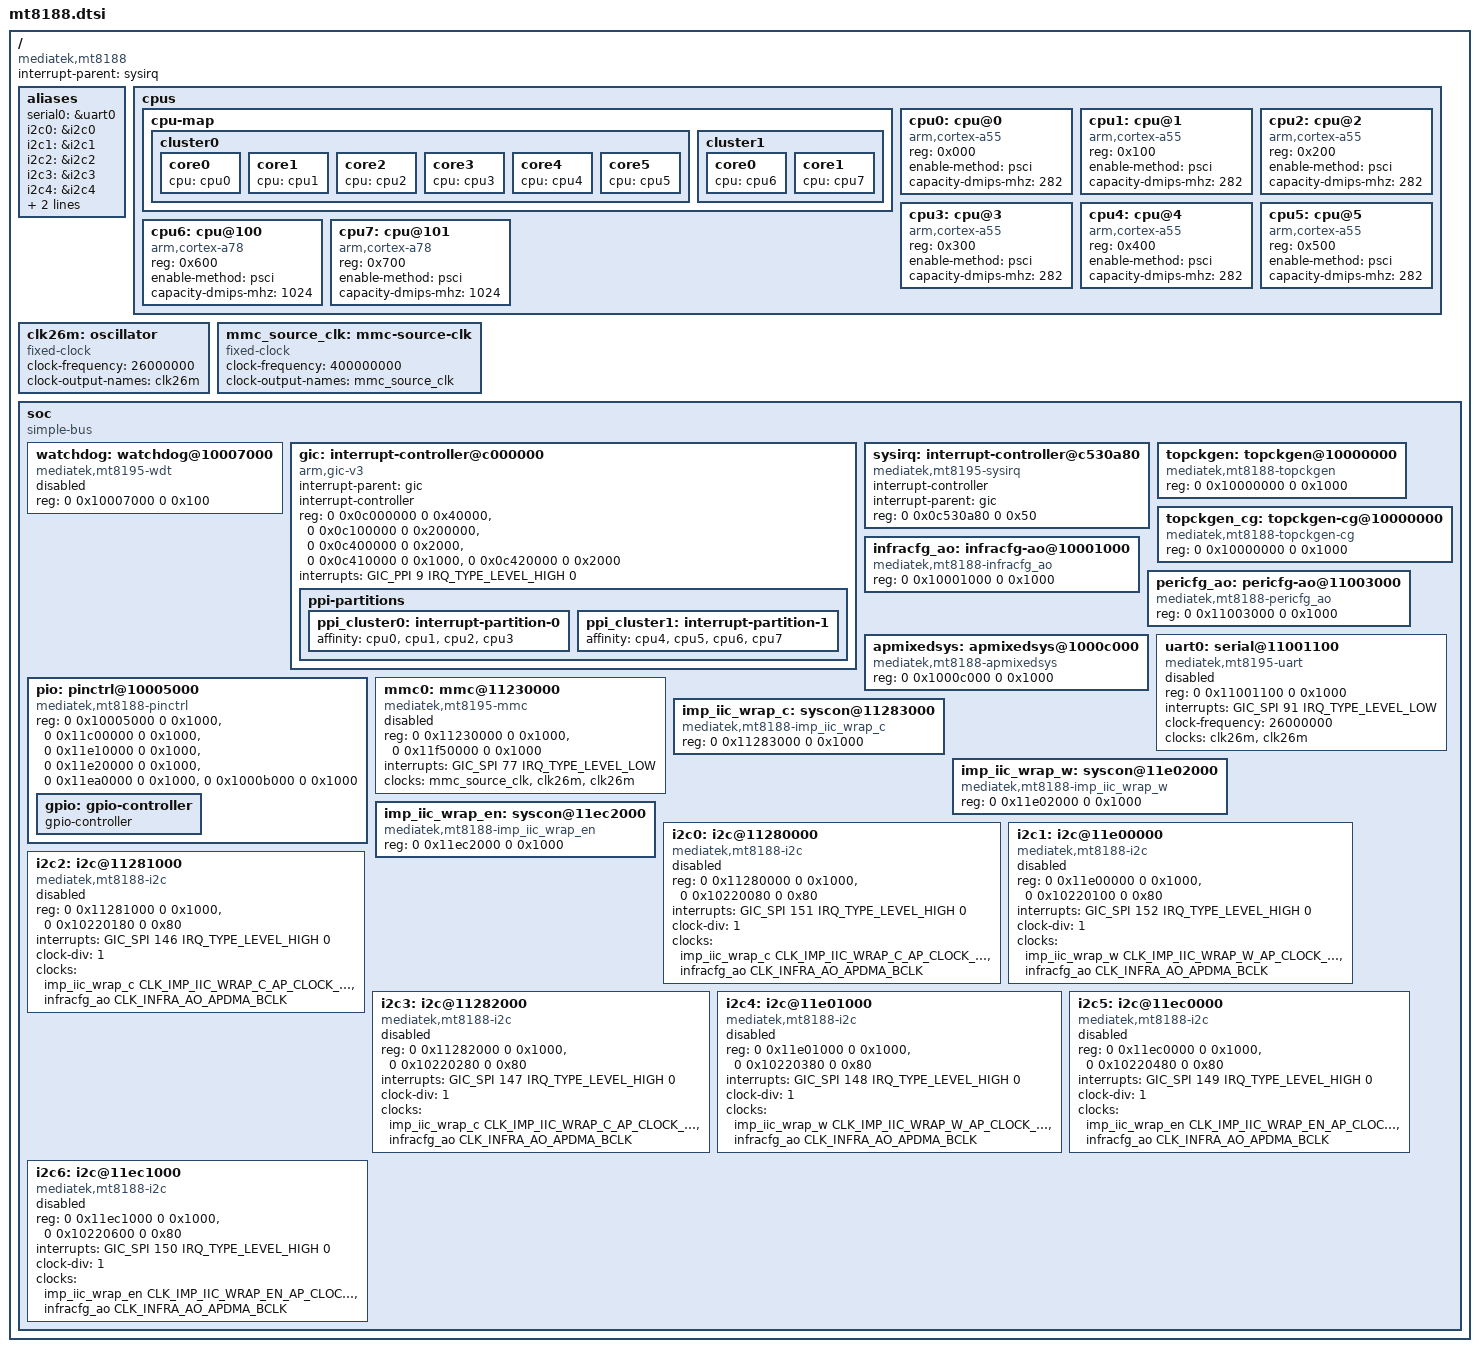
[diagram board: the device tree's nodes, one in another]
// SPDX-License-Identifier: (GPL-2.0 OR MIT)
/*
 * Copyright (C) 2022 MediaTek Inc.
 * Author: Chris-QJ Chen <chris-qj.chen@mediatek.com>
 *         Macpaul Lin <macpaul.lin@mediatek.com>
 */

#include <dt-bindings/gpio/gpio.h>
#include <dt-bindings/clock/mt8188-clk.h>
#include <dt-bindings/interrupt-controller/irq.h>
#include <dt-bindings/interrupt-controller/arm-gic.h>
#include <dt-bindings/pinctrl/mediatek,mt8188-pinfunc.h>
#include <dt-bindings/phy/phy.h>

/ {
	compatible = "mediatek,mt8188";
	interrupt-parent = <&sysirq>;
	#address-cells = <2>;
	#size-cells = <2>;

	aliases {
		serial0 = &uart0;
		i2c0 = &i2c0;
		i2c1 = &i2c1;
		i2c2 = &i2c2;
		i2c3 = &i2c3;
		i2c4 = &i2c4;
		i2c5 = &i2c5;
		i2c6 = &i2c6;
	};

	cpus {
		#address-cells = <1>;
		#size-cells = <0>;

		cpu-map {
			cluster0 {
				core0 {
					cpu = <&cpu0>;
				};
				core1 {
					cpu = <&cpu1>;
				};
				core2 {
					cpu = <&cpu2>;
				};
				core3 {
					cpu = <&cpu3>;
				};
				core4 {
					cpu = <&cpu4>;
				};
				core5 {
					cpu = <&cpu5>;
				};
			};
			cluster1 {
				core0 {
					cpu = <&cpu6>;
				};
				core1 {
					cpu = <&cpu7>;
				};
			};
		};

		cpu0: cpu@0 {
			device_type = "cpu";
			compatible = "arm,cortex-a55", "arm,armv8";
			reg = <0x000>;
			enable-method = "psci";
			capacity-dmips-mhz = <282>;
		};

		cpu1: cpu@1 {
			device_type = "cpu";
			compatible = "arm,cortex-a55", "arm,armv8";
			reg = <0x100>;
			enable-method = "psci";
			capacity-dmips-mhz = <282>;
		};

		cpu2: cpu@2 {
			device_type = "cpu";
			compatible = "arm,cortex-a55", "arm,armv8";
			reg = <0x200>;
			enable-method = "psci";
			capacity-dmips-mhz = <282>;
		};

		cpu3: cpu@3 {
			device_type = "cpu";
			compatible = "arm,cortex-a55", "arm,armv8";
			reg = <0x300>;
			enable-method = "psci";
			capacity-dmips-mhz = <282>;
		};

		cpu4: cpu@4 {
			device_type = "cpu";
			compatible = "arm,cortex-a55", "arm,armv8";
			reg = <0x400>;
			enable-method = "psci";
			capacity-dmips-mhz = <282>;
		};

		cpu5: cpu@5 {
			device_type = "cpu";
			compatible = "arm,cortex-a55", "arm,armv8";
			reg = <0x500>;
			enable-method = "psci";
			capacity-dmips-mhz = <282>;
		};

		cpu6: cpu@100 {
			device_type = "cpu";
			compatible = "arm,cortex-a78", "arm,armv8";
			reg = <0x600>;
			enable-method = "psci";
			capacity-dmips-mhz = <1024>;
		};

		cpu7: cpu@101 {
			device_type = "cpu";
			compatible = "arm,cortex-a78", "arm,armv8";
			reg = <0x700>;
			enable-method = "psci";
			capacity-dmips-mhz = <1024>;
		};
	};

	clk26m: oscillator {
		compatible = "fixed-clock";
		#clock-cells = <0>;
		clock-frequency = <26000000>;
		clock-output-names = "clk26m";
	};

	mmc_source_clk: mmc-source-clk{
		compatible = "fixed-clock";
		#clock-cells = <0>;
		clock-frequency = <400000000>;
		clock-output-names = "mmc_source_clk";
	};

	soc {
		#address-cells = <2>;
		#size-cells = <2>;
		compatible = "simple-bus";
		ranges;

		watchdog: watchdog@10007000 {
			compatible = "mediatek,mt8195-wdt",
				      "mediatek,wdt";
			reg = <0 0x10007000 0 0x100>;
			status = "disabled";
		};

		gic: interrupt-controller@c000000 {
			compatible = "arm,gic-v3";
			#interrupt-cells = <4>;
			interrupt-parent = <&gic>;
			interrupt-controller;
			reg = <0 0x0c000000 0 0x40000>,  /* GICD */
			      <0 0x0c100000 0 0x200000>, /* GICR */
			      <0 0x0c400000 0 0x2000>,   /* GICC */
			      <0 0x0c410000 0 0x1000>,   /* GICH */
			      <0 0x0c420000 0 0x2000>;   /* GICV */

			interrupts = <GIC_PPI 9 IRQ_TYPE_LEVEL_HIGH 0>;
			ppi-partitions {
				ppi_cluster0: interrupt-partition-0 {
					affinity = <&cpu0 &cpu1 &cpu2 &cpu3>;
				};
				ppi_cluster1: interrupt-partition-1 {
					affinity = <&cpu4 &cpu5 &cpu6 &cpu7>;
				};
			};
		};

		sysirq: interrupt-controller@c530a80 {
			compatible = "mediatek,mt8195-sysirq",
				     "mediatek,mt6577-sysirq";
			interrupt-controller;
			#interrupt-cells = <3>;
			interrupt-parent = <&gic>;
			reg = <0 0x0c530a80 0 0x50>;
		};

		topckgen: topckgen@10000000 {
			compatible = "mediatek,mt8188-topckgen";
			reg = <0 0x10000000 0 0x1000>;
			#clock-cells = <1>;
		};

		topckgen_cg: topckgen-cg@10000000 {
			compatible = "mediatek,mt8188-topckgen-cg";
			reg = <0 0x10000000 0 0x1000>;
			#clock-cells = <1>;
		};

		infracfg_ao: infracfg-ao@10001000 {
			compatible = "mediatek,mt8188-infracfg_ao";
			reg = <0 0x10001000 0 0x1000>;
			#clock-cells = <1>;
		};

		pericfg_ao: pericfg-ao@11003000 {
			compatible = "mediatek,mt8188-pericfg_ao";
			reg = <0 0x11003000 0 0x1000>;
			#clock-cells = <1>;
		};

		apmixedsys: apmixedsys@1000c000 {
			compatible = "mediatek,mt8188-apmixedsys";
			reg = <0 0x1000c000 0 0x1000>;
			#clock-cells = <1>;
		};

		pio: pinctrl@10005000 {
			compatible = "mediatek,mt8188-pinctrl";
			reg = <0 0x10005000 0 0x1000>,
			<0 0x11c00000 0 0x1000>,
			<0 0x11e10000 0 0x1000>,
			<0 0x11e20000 0 0x1000>,
			<0 0x11ea0000 0 0x1000>,
			<0 0x1000b000 0 0x1000>;
			reg-names = "iocfg0", "iocfg_rm", "iocfg_lt",
				    "iocfg_lm", "iocfg_rt", "eint";
			gpio: gpio-controller {
				gpio-controller;
				#gpio-cells = <2>;
			};
		};

		uart0: serial@11001100 {
			compatible = "mediatek,mt8195-uart",
				     "mediatek,hsuart";
			reg = <0 0x11001100 0 0x1000>;
			interrupts = <GIC_SPI 91 IRQ_TYPE_LEVEL_LOW>;
			clock-frequency = <26000000>;
			clocks = <&clk26m>, <&clk26m>;
			clock-names = "baud", "bus";
			status = "disabled";
		};

		mmc0: mmc@11230000 {
			compatible = "mediatek,mt8195-mmc",
				     "mediatek,mt8183-mmc";
			reg = <0 0x11230000 0 0x1000>,
			      <0 0x11f50000 0 0x1000>;
			interrupts = <GIC_SPI 77 IRQ_TYPE_LEVEL_LOW>;
			clocks = <&mmc_source_clk>,
				 <&clk26m>,
				 <&clk26m>;
			clock-names = "source", "hclk", "source_cg";
			status = "disabled";
		};

		imp_iic_wrap_c: syscon@11283000 {
			compatible = "mediatek,mt8188-imp_iic_wrap_c";
			reg = <0 0x11283000 0 0x1000>;
			#clock-cells = <1>;
		};

		imp_iic_wrap_w: syscon@11e02000 {
			compatible = "mediatek,mt8188-imp_iic_wrap_w";
			reg = <0 0x11e02000 0 0x1000>;
			#clock-cells = <1>;
		};

		imp_iic_wrap_en: syscon@11ec2000 {
			compatible = "mediatek,mt8188-imp_iic_wrap_en";
			reg = <0 0x11ec2000 0 0x1000>;
			#clock-cells = <1>;
		};

		i2c0: i2c@11280000 {
			compatible = "mediatek,mt8188-i2c";
			reg = <0 0x11280000 0 0x1000>,
			      <0 0x10220080 0 0x80>;
			interrupts = <GIC_SPI 151 IRQ_TYPE_LEVEL_HIGH 0>;
			clock-div = <1>;
			clocks = <&imp_iic_wrap_c CLK_IMP_IIC_WRAP_C_AP_CLOCK_I2C0>,
				 <&infracfg_ao CLK_INFRA_AO_APDMA_BCLK>;
			clock-names = "main", "dma";
			#address-cells = <1>;
			#size-cells = <0>;
			status = "disabled";
		};

		i2c1: i2c@11e00000 {
			compatible = "mediatek,mt8188-i2c";
			reg = <0 0x11e00000 0 0x1000>,
			      <0 0x10220100 0 0x80>;
			interrupts = <GIC_SPI 152 IRQ_TYPE_LEVEL_HIGH 0>;
			clock-div = <1>;
			clocks = <&imp_iic_wrap_w CLK_IMP_IIC_WRAP_W_AP_CLOCK_I2C1>,
				 <&infracfg_ao CLK_INFRA_AO_APDMA_BCLK>;
			clock-names = "main", "dma";
			#address-cells = <1>;
			#size-cells = <0>;
			status = "disabled";
		};

		i2c2: i2c@11281000 {
			compatible = "mediatek,mt8188-i2c";
			reg = <0 0x11281000 0 0x1000>,
				<0 0x10220180 0 0x80>;
			interrupts = <GIC_SPI 146 IRQ_TYPE_LEVEL_HIGH 0>;
			clock-div = <1>;
			clocks = <&imp_iic_wrap_c CLK_IMP_IIC_WRAP_C_AP_CLOCK_I2C2>,
				 <&infracfg_ao CLK_INFRA_AO_APDMA_BCLK>;
			clock-names = "main", "dma";
			#address-cells = <1>;
			#size-cells = <0>;
			status = "disabled";
		};

		i2c3: i2c@11282000 {
			compatible = "mediatek,mt8188-i2c";
			reg = <0 0x11282000 0 0x1000>,
			      <0 0x10220280 0 0x80>;
			interrupts = <GIC_SPI 147 IRQ_TYPE_LEVEL_HIGH 0>;
			clock-div = <1>;
			clocks = <&imp_iic_wrap_c CLK_IMP_IIC_WRAP_C_AP_CLOCK_I2C3>,
				 <&infracfg_ao CLK_INFRA_AO_APDMA_BCLK>;
			clock-names = "main", "dma";
			#address-cells = <1>;
			#size-cells = <0>;
			status = "disabled";
		};

		i2c4: i2c@11e01000 {
			compatible = "mediatek,mt8188-i2c";
			reg = <0 0x11e01000 0 0x1000>,
			      <0 0x10220380 0 0x80>;
			interrupts = <GIC_SPI 148 IRQ_TYPE_LEVEL_HIGH 0>;
			clock-div = <1>;
			clocks = <&imp_iic_wrap_w CLK_IMP_IIC_WRAP_W_AP_CLOCK_I2C4>,
				 <&infracfg_ao CLK_INFRA_AO_APDMA_BCLK>;
			clock-names = "main", "dma";
			#address-cells = <1>;
			#size-cells = <0>;
			status = "disabled";
		};

		i2c5: i2c@11ec0000 {
			compatible = "mediatek,mt8188-i2c";
			reg = <0 0x11ec0000 0 0x1000>,
			      <0 0x10220480 0 0x80>;
			interrupts = <GIC_SPI 149 IRQ_TYPE_LEVEL_HIGH 0>;
			clock-div = <1>;
			clocks = <&imp_iic_wrap_en CLK_IMP_IIC_WRAP_EN_AP_CLOCK_I2C5>,
				 <&infracfg_ao CLK_INFRA_AO_APDMA_BCLK>;
			clock-names = "main", "dma";
			#address-cells = <1>;
			#size-cells = <0>;
			status = "disabled";
		};

		i2c6: i2c@11ec1000 {
			compatible = "mediatek,mt8188-i2c";
			reg = <0 0x11ec1000 0 0x1000>,
			      <0 0x10220600 0 0x80>;
			interrupts = <GIC_SPI 150 IRQ_TYPE_LEVEL_HIGH 0>;
			clock-div = <1>;
			clocks = <&imp_iic_wrap_en CLK_IMP_IIC_WRAP_EN_AP_CLOCK_I2C6>,
				 <&infracfg_ao CLK_INFRA_AO_APDMA_BCLK>;
			clock-names = "main", "dma";
			#address-cells = <1>;
			#size-cells = <0>;
			status = "disabled";
		};

	};
};
